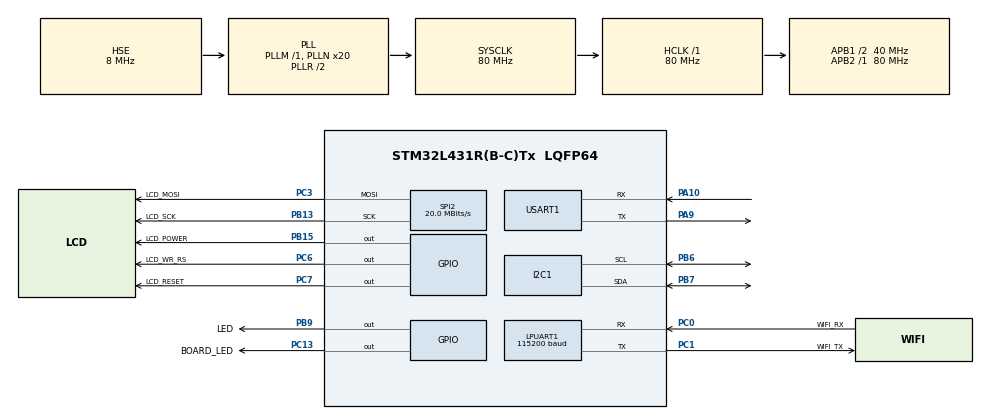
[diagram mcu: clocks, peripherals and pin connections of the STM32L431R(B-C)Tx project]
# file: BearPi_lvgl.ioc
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Dma.LPUART_RX.0.Direction=DMA_PERIPH_TO_MEMORY
Dma.LPUART_RX.0.Instance=DMA2_Channel7
Dma.LPUART_RX.0.MemDataAlignment=DMA_MDATAALIGN_BYTE
Dma.LPUART_RX.0.MemInc=DMA_MINC_ENABLE
Dma.LPUART_RX.0.Mode=DMA_NORMAL
Dma.LPUART_RX.0.PeriphDataAlignment=DMA_PDATAALIGN_BYTE
Dma.LPUART_RX.0.PeriphInc=DMA_PINC_DISABLE
Dma.LPUART_RX.0.Priority=DMA_PRIORITY_LOW
Dma.Request0=LPUART_RX
I2C1.Timing=0x00909BEB
LPUART1.BaudRate=115200
LPUART1.WordLength=UART_WORDLENGTH_8B
Mcu.Family=STM32L4
Mcu.Name=STM32L431R(B-C)Tx
Mcu.Package=LQFP64
NVIC.DMA2_Channel7_IRQn=true\:0\:0\:false\:false\:true\:false\:true
NVIC.LPUART1_IRQn=true\:0\:0\:false\:false\:true\:true\:true
NVIC.PriorityGroup=NVIC_PRIORITYGROUP_4
PA10.Mode=Asynchronous
PA10.Signal=USART1_RX
PA13\ (JTMS-SWDIO).Mode=Serial_Wire
PA13\ (JTMS-SWDIO).Signal=SYS_JTMS-SWDIO
PA14\ (JTCK-SWCLK).Mode=Serial_Wire
PA14\ (JTCK-SWCLK).Signal=SYS_JTCK-SWCLK
PA9.Mode=Asynchronous
PA9.Signal=USART1_TX
PB13.GPIO_Label=LCD_SCK
PB13.Mode=TX_Only_Simplex_Unidirect_Master
PB13.Signal=SPI2_SCK
PB15.GPIO_Label=LCD_POWER
PB15.GPIO_Speed=GPIO_SPEED_FREQ_VERY_HIGH
PB15.PinState=GPIO_PIN_SET
PB15.Signal=GPIO_Output
PB6.Mode=I2C
PB6.Signal=I2C1_SCL
PB7.Mode=I2C
PB7.Signal=I2C1_SDA
PB9.GPIO_Label=LED
PB9.GPIO_Speed=GPIO_SPEED_FREQ_VERY_HIGH
PB9.Signal=GPIO_Output
PC0.GPIO_Label=WIFI_RX
PC0.Mode=Asynchronous
PC0.Signal=LPUART1_RX
PC1.GPIO_Label=WIFI_TX
PC1.Mode=Asynchronous
PC1.Signal=LPUART1_TX
PC13.GPIO_Label=BOARD_LED
PC13.Signal=GPIO_Output
PC3.GPIO_Label=LCD_MOSI
PC3.Mode=TX_Only_Simplex_Unidirect_Master
PC3.Signal=SPI2_MOSI
PC6.GPIO_Label=LCD_WR_RS
PC6.GPIO_Speed=GPIO_SPEED_FREQ_VERY_HIGH
PC6.Signal=GPIO_Output
PC7.GPIO_Label=LCD_RESET
PC7.GPIO_Speed=GPIO_SPEED_FREQ_VERY_HIGH
PC7.PinState=GPIO_PIN_RESET
PC7.Signal=GPIO_Output
PH0-OSC_IN\ (PH0).Mode=HSE-External-Oscillator
PH0-OSC_IN\ (PH0).Signal=RCC_OSC_IN
PH1-OSC_OUT\ (PH1).Mode=HSE-External-Oscillator
PH1-OSC_OUT\ (PH1).Signal=RCC_OSC_OUT
ProjectManager.HeapSize=0x200
ProjectManager.StackSize=0x800
ProjectManager.TargetToolchain=MDK-ARM V5
RCC.ADCFreq_Value=32000000
RCC.AHBFreq_Value=80000000
RCC.APB1CLKDivider=RCC_HCLK_DIV2
RCC.APB1Freq_Value=40000000
RCC.APB1TimFreq_Value=80000000
RCC.APB2Freq_Value=80000000
RCC.APB2TimFreq_Value=80000000
RCC.CortexFreq_Value=80000000
RCC.HCLKFreq_Value=80000000
RCC.HSE_VALUE=8000000
RCC.HSI48_VALUE=48000000
RCC.HSI_VALUE=16000000
RCC.LSE_VALUE=32768
RCC.MSI_VALUE=4000000
RCC.PLLN=20
RCC.PLLSourceVirtual=RCC_PLLSOURCE_HSE
RCC.SYSCLKFreq_VALUE=80000000
RCC.SYSCLKSource=RCC_SYSCLKSOURCE_PLLCLK
RCC.VCOOutputFreq_Value=160000000
SPI2.BaudRatePrescaler=SPI_BAUDRATEPRESCALER_2
SPI2.CLKPhase=SPI_PHASE_2EDGE
SPI2.CLKPolarity=SPI_POLARITY_HIGH
SPI2.CalculateBaudRate=20.0 MBits/s
SPI2.DataSize=SPI_DATASIZE_8BIT
SPI2.Direction=SPI_DIRECTION_2LINES
SPI2.Mode=SPI_MODE_MASTER
SPI2.VirtualType=VM_MASTER
USART1.VirtualMode-Asynchronous=VM_ASYNC
board=custom

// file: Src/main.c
/* USER CODE BEGIN Header */
/**
  ******************************************************************************
  * @file           : main.c
  * @brief          : Main program body
  ******************************************************************************
  * @attention
  *
  * <h2><center>&copy; Copyright (c) 2020 STMicroelectronics.
  * All rights reserved.</center></h2>
  *
  * This software component is licensed by ST under BSD 3-Clause license,
  * the "License"; You may not use this file except in compliance with the
  * License. You may obtain a copy of the License at:
  *                        opensource.org/licenses/BSD-3-Clause
  *
  ******************************************************************************
  */
/* USER CODE END Header */

#include "main.h"
#include "dma.h"
#include "i2c.h"
#include "usart.h"
#include "spi.h"
#include "gpio.h"

/* USER CODE BEGIN Includes */
#include "lcd.h"
#include "HzLib.h"
#include "lvgl.h"
#include "demo.h"
#include "lv_port_disp.h"
#include "lv_tests\lv_test_theme\lv_test_theme_1.h"
#include "lv_tests\lv_test_theme\lv_test_theme_2.h"
#include "gui_app.h"
/* USER CODE END Includes */

void SystemClock_Config(void);

/* USER CODE BEGIN 0 */
#define LV_USE_TESTS 1
/* USER CODE END 0 */

int main(void)
{

    /* MCU Configuration--------------------------------------------------------*/

    /* Reset of all peripherals, Initializes the Flash interface and the Systick. */
    HAL_Init();

    /* Configure the system clock */
    SystemClock_Config();

    /* Initialize all configured peripherals */
    MX_GPIO_Init();
    MX_DMA_Init();
    MX_I2C1_Init();
    MX_USART1_UART_Init();
    MX_LPUART1_UART_Init();
    MX_SPI2_Init();
    /* USER CODE BEGIN 2 */
	lv_init();
	lv_port_disp_init();
	//demo_create();	//�㲻��
	//lv_test_theme_1(lv_theme_night_init(10, NULL));	//demo1
	//lv_test_theme_2();								//demo2
	//gui_app_start();									//demo3	����ԭ���ۺ�����
	//lv_test_theme_1(lv_theme_mono_init(10,NULL));
	//lv_test_theme_1(lv_theme_templ_init(10,NULL));
	//lv_test_theme_1(lv_theme_material_init(10,NULL));
	//lv_test_theme_1(lv_theme_alien_init(10,NULL));
	//lv_test_theme_1(lv_theme_zen_init(10,NULL));
	//lv_test_theme_1(lv_theme_default_init(10,NULL));
	//lv_test_theme_1(lv_theme_nemo_init(10,NULL));
	lv_test_theme_1(lv_theme_night_init(10,NULL));
    /* USER CODE END 2 */

    /* Infinite loop */
    while (1)
    {

        /* USER CODE BEGIN 3 */
		lv_task_handler();
    }

    /* USER CODE END 3 */
}

void SystemClock_Config(void)
{
    RCC_OscInitTypeDef RCC_OscInitStruct = {0};
    RCC_ClkInitTypeDef RCC_ClkInitStruct = {0};
    RCC_PeriphCLKInitTypeDef PeriphClkInit = {0};

    /** Initializes the CPU, AHB and APB busses clocks
    */
    RCC_OscInitStruct.OscillatorType = RCC_OSCILLATORTYPE_HSE;
    RCC_OscInitStruct.HSEState = RCC_HSE_ON;
    RCC_OscInitStruct.PLL.PLLState = RCC_PLL_ON;
    RCC_OscInitStruct.PLL.PLLSource = RCC_PLLSOURCE_HSE;
    RCC_OscInitStruct.PLL.PLLM = 1;
    RCC_OscInitStruct.PLL.PLLN = 20;
    RCC_OscInitStruct.PLL.PLLP = RCC_PLLP_DIV7;
    RCC_OscInitStruct.PLL.PLLQ = RCC_PLLQ_DIV2;
    RCC_OscInitStruct.PLL.PLLR = RCC_PLLR_DIV2;

    if (HAL_RCC_OscConfig(&RCC_OscInitStruct) != HAL_OK)
    {
        Error_Handler();
    }

    /** Initializes the CPU, AHB and APB busses clocks
    */
    RCC_ClkInitStruct.ClockType = RCC_CLOCKTYPE_HCLK | RCC_CLOCKTYPE_SYSCLK
                                  | RCC_CLOCKTYPE_PCLK1 | RCC_CLOCKTYPE_PCLK2;
    RCC_ClkInitStruct.SYSCLKSource = RCC_SYSCLKSOURCE_PLLCLK;
    RCC_ClkInitStruct.AHBCLKDivider = RCC_SYSCLK_DIV1;
    RCC_ClkInitStruct.APB1CLKDivider = RCC_HCLK_DIV2;
    RCC_ClkInitStruct.APB2CLKDivider = RCC_HCLK_DIV1;

    if (HAL_RCC_ClockConfig(&RCC_ClkInitStruct, FLASH_LATENCY_4) != HAL_OK)
    {
        Error_Handler();
    }

    PeriphClkInit.PeriphClockSelection = RCC_PERIPHCLK_USART1 | RCC_PERIPHCLK_LPUART1
                                         | RCC_PERIPHCLK_I2C1;
    PeriphClkInit.Usart1ClockSelection = RCC_USART1CLKSOURCE_PCLK2;
    PeriphClkInit.Lpuart1ClockSelection = RCC_LPUART1CLKSOURCE_PCLK1;
    PeriphClkInit.I2c1ClockSelection = RCC_I2C1CLKSOURCE_PCLK1;

    if (HAL_RCCEx_PeriphCLKConfig(&PeriphClkInit) != HAL_OK)
    {
        Error_Handler();
    }

    /** Configure the main internal regulator output voltage
    */
    if (HAL_PWREx_ControlVoltageScaling(PWR_REGULATOR_VOLTAGE_SCALE1) != HAL_OK)
    {
        Error_Handler();
    }
}

void Error_Handler(void)
{
}

/************************ (C) COPYRIGHT STMicroelectronics *****END OF FILE****/
